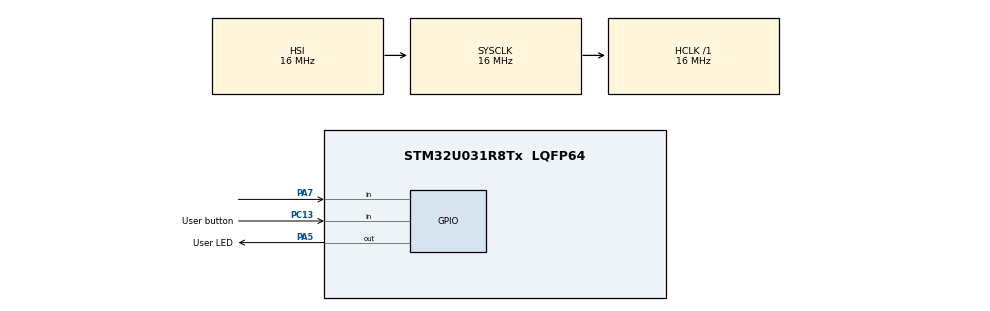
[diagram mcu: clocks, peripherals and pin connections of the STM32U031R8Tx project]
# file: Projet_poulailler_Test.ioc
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Mcu.Family=STM32U0
Mcu.Name=STM32U031R8Tx
Mcu.Package=LQFP64
NVIC.PriorityGroup=NVIC_PRIORITYGROUP_2
PA13\ (SWDIO).GPIO_Label=SWDIO
PA13\ (SWDIO).Signal=DEBUG_JTMS-SWDIO
PA14\ (SWCLK).GPIO_Label=SWCLK
PA14\ (SWCLK).Signal=DEBUG_JTCK-SWCLK
PA2.GPIO_Label=USART2_TX
PA2.Signal=USART2_TX
PA3.GPIO_Label=USART2_RX
PA3.Signal=USART2_RX
PA5.GPIO_Label=User LED
PA5.Signal=GPIO_Output
PA7.Signal=GPIO_Input
PB8.GPIO_Label=I2C1_SCL
PB8.Signal=I2C1_SCL
PB9.GPIO_Label=I2C1_SDA
PB9.Signal=I2C1_SDA
PC13.GPIO_Label=User button
PC13.Signal=GPIO_Input
PC14-OSC32_IN.GPIO_Label=OSC32_IN
PC14-OSC32_IN.Signal=RCC_OSC32_IN
PC15-OSC32_OUT.GPIO_Label=OSC32_OUT
PC15-OSC32_OUT.Signal=RCC_OSC32_OUT
PF0-OSC_IN.GPIO_Label=OSC_IN
PF0-OSC_IN.Signal=RCC_OSC_IN
PF1-OSC_OUT.GPIO_Label=OSC_OUT
PF1-OSC_OUT.Signal=RCC_OSC_OUT
ProjectManager.HeapSize=0x200
ProjectManager.StackSize=0x400
ProjectManager.TargetToolchain=STM32CubeIDE
RCC.AHBFreq_Value=16000000
RCC.CortexFreq_Value=16000000
RCC.HCLKFreq_Value=16000000
RCC.HSE_VALUE=4000000
RCC.HSI48_VALUE=48000000
RCC.HSI_VALUE=16000000
RCC.LSE_VALUE=32768
RCC.MSI_VALUE=4000000
RCC.SYSCLKFreq_VALUE=16000000
RCC.VCOOutputFreq_Value=64000000
VP_PWR_VS_SECSignals.Mode=Security/Privilege
board=NUCLEO-U031R8

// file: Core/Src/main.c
/* USER CODE BEGIN Header */
/**
  ******************************************************************************
  * @file           : main.c
  * @brief          : Main program body
  ******************************************************************************
  * @attention
  *
  * Copyright (c) 2025 STMicroelectronics.
  * All rights reserved.
  *
  * This software is licensed under terms that can be found in the LICENSE file
  * in the root directory of this software component.
  * If no LICENSE file comes with this software, it is provided AS-IS.
  *
  ******************************************************************************
  */
/* USER CODE END Header */
#include "main.h"

void SystemClock_Config(void);
static void MX_GPIO_Init(void);

int main(void)
{

  /* MCU Configuration--------------------------------------------------------*/

  /* Reset of all peripherals, Initializes the Flash interface and the Systick. */
  HAL_Init();

  /* Configure the system clock */
  SystemClock_Config();

  /* Initialize all configured peripherals */
  MX_GPIO_Init();

  /* Infinite loop */
  while (1)
  {

  }
}

void SystemClock_Config(void)
{
  RCC_OscInitTypeDef RCC_OscInitStruct = {0};
  RCC_ClkInitTypeDef RCC_ClkInitStruct = {0};

  /** Configure the main internal regulator output voltage
  */
  HAL_PWREx_ControlVoltageScaling(PWR_REGULATOR_VOLTAGE_SCALE2);

  /** Initializes the RCC Oscillators according to the specified parameters
  * in the RCC_OscInitTypeDef structure.
  */
  RCC_OscInitStruct.OscillatorType = RCC_OSCILLATORTYPE_HSI;
  RCC_OscInitStruct.HSIState = RCC_HSI_ON;
  RCC_OscInitStruct.HSICalibrationValue = RCC_HSICALIBRATION_DEFAULT;
  RCC_OscInitStruct.PLL.PLLState = RCC_PLL_NONE;
  if (HAL_RCC_OscConfig(&RCC_OscInitStruct) != HAL_OK)
  {
    Error_Handler();
  }

  /** Initializes the CPU, AHB and APB buses clocks
  */
  RCC_ClkInitStruct.ClockType = RCC_CLOCKTYPE_HCLK|RCC_CLOCKTYPE_SYSCLK
                              |RCC_CLOCKTYPE_PCLK1;
  RCC_ClkInitStruct.SYSCLKSource = RCC_SYSCLKSOURCE_HSI;
  RCC_ClkInitStruct.AHBCLKDivider = RCC_SYSCLK_DIV1;
  RCC_ClkInitStruct.APB1CLKDivider = RCC_HCLK_DIV1;

  if (HAL_RCC_ClockConfig(&RCC_ClkInitStruct, FLASH_LATENCY_1) != HAL_OK)
  {
    Error_Handler();
  }
}

static void MX_GPIO_Init(void)
{
  GPIO_InitTypeDef GPIO_InitStruct = {0};

  /* GPIO Ports Clock Enable */
  __HAL_RCC_GPIOC_CLK_ENABLE();
  __HAL_RCC_GPIOF_CLK_ENABLE();
  __HAL_RCC_GPIOA_CLK_ENABLE();
  __HAL_RCC_GPIOB_CLK_ENABLE();

  /*Configure GPIO pin Output Level */
  HAL_GPIO_WritePin(User_LED_GPIO_Port, User_LED_Pin, GPIO_PIN_RESET);

  /*Configure GPIO pin : User_button_Pin */
  GPIO_InitStruct.Pin = User_button_Pin;
  GPIO_InitStruct.Mode = GPIO_MODE_INPUT;
  GPIO_InitStruct.Pull = GPIO_NOPULL;
  HAL_GPIO_Init(User_button_GPIO_Port, &GPIO_InitStruct);

  /*Configure GPIO pins : USART2_TX_Pin USART2_RX_Pin */
  GPIO_InitStruct.Pin = USART2_TX_Pin|USART2_RX_Pin;
  GPIO_InitStruct.Mode = GPIO_MODE_AF_PP;
  GPIO_InitStruct.Pull = GPIO_NOPULL;
  GPIO_InitStruct.Speed = GPIO_SPEED_FREQ_LOW;
  GPIO_InitStruct.Alternate = GPIO_AF7_USART2;
  HAL_GPIO_Init(GPIOA, &GPIO_InitStruct);

  /*Configure GPIO pin : User_LED_Pin */
  GPIO_InitStruct.Pin = User_LED_Pin;
  GPIO_InitStruct.Mode = GPIO_MODE_OUTPUT_PP;
  GPIO_InitStruct.Pull = GPIO_NOPULL;
  GPIO_InitStruct.Speed = GPIO_SPEED_FREQ_LOW;
  HAL_GPIO_Init(User_LED_GPIO_Port, &GPIO_InitStruct);

  /*Configure GPIO pin : PA7 */
  GPIO_InitStruct.Pin = GPIO_PIN_7;
  GPIO_InitStruct.Mode = GPIO_MODE_INPUT;
  GPIO_InitStruct.Pull = GPIO_NOPULL;
  HAL_GPIO_Init(GPIOA, &GPIO_InitStruct);

  /*Configure GPIO pins : I2C1_SCL_Pin I2C1_SDA_Pin */
  GPIO_InitStruct.Pin = I2C1_SCL_Pin|I2C1_SDA_Pin;
  GPIO_InitStruct.Mode = GPIO_MODE_AF_OD;
  GPIO_InitStruct.Pull = GPIO_NOPULL;
  GPIO_InitStruct.Speed = GPIO_SPEED_FREQ_LOW;
  GPIO_InitStruct.Alternate = GPIO_AF4_I2C1;
  HAL_GPIO_Init(GPIOB, &GPIO_InitStruct);

}

/* USER CODE BEGIN 4 */
//test 2 branche Rom1
/* USER CODE END 4 */

void Error_Handler(void)
{
  __disable_irq();
  while (1)
  {
  }
}
